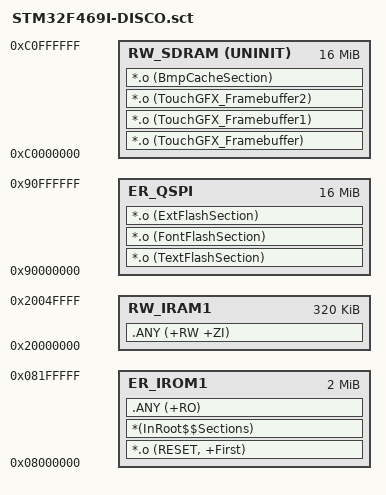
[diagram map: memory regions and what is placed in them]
; *************************************************************
; *** Scatter-Loading Description File generated by uVision ***
; *************************************************************

LR_IROM1 0x08000000 0x00200000  {    ; load region size_region
  ER_IROM1 0x08000000 0x00200000  {  ; load address = execution address
   *.o (RESET, +First)
   *(InRoot$$Sections)
   .ANY (+RO)
  }
  RW_IRAM1 0x20000000 0x00050000  {  ; RW data
   .ANY (+RW +ZI)
  }
  RW_SDRAM 0xC0000000 UNINIT 0x01000000 {
   *.o (TouchGFX_Framebuffer)
   *.o (TouchGFX_Framebuffer1)
   *.o (TouchGFX_Framebuffer2)
   *.o (BmpCacheSection)
  }
}

LR_QSPI 0x90000000 0x01000000  {    ; load region size_region
  ER_QSPI 0x90000000 0x01000000  {  ; load address = execution address
   *.o (TextFlashSection)
   *.o (FontFlashSection)
   *.o (ExtFlashSection)
  }
}
